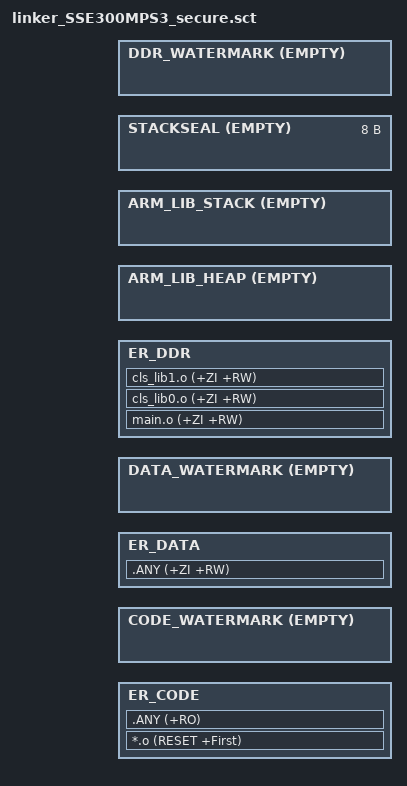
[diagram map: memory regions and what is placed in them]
#! armclang --target=arm-arm-none-eabi -march=armv8.1-m.main -E -xc

;/*
; * Copyright (c) 2018-2023 Arm Limited
; *
; * Licensed under the Apache License, Version 2.0 (the "License");
; * you may not use this file except in compliance with the License.
; * You may obtain a copy of the License at
; *
; *     http://www.apache.org/licenses/LICENSE-2.0
; *
; * Unless required by applicable law or agreed to in writing, software
; * distributed under the License is distributed on an "AS IS" BASIS,
; * WITHOUT WARRANTIES OR CONDITIONS OF ANY KIND, either express or implied.
; * See the License for the specific language governing permissions and
; * limitations under the License.
; *
; */
#include "region_defs.h"

LR_CODE S_CODE_START {
    ER_CODE S_CODE_START {
        *.o (RESET +First)
        .ANY (+RO)
    }
    CODE_WATERMARK +0 EMPTY 0x0 {
    }
    ScatterAssert(ImageLimit(CODE_WATERMARK) <= S_CODE_LIMIT)

    ER_DATA S_DATA_START {
        .ANY (+ZI +RW)
    }
    DATA_WATERMARK +0 EMPTY 0x0 {
    }
    ScatterAssert(ImageLimit(DATA_WATERMARK) <= S_DATA_LIMIT)
	
	ER_DDR S_DDR4_START {
		main.o (+ZI +RW)
		cls_lib0.o (+ZI +RW)
		cls_lib1.o (+ZI +RW)
    }
    ARM_LIB_HEAP +0 ALIGN 8 EMPTY  HEAP_SIZE  {   ; Reserve empty region for heap
    }
    ARM_LIB_STACK +0 ALIGN 32 EMPTY STACK_SIZE - 0x8 {   ; Reserve empty region for stack
    }
    STACKSEAL +0 EMPTY 0x8 {
    }
    DDR_WATERMARK +0 EMPTY 0x0 {
    }
    ScatterAssert(ImageLimit(DDR_WATERMARK) <= S_DDR4_LIMIT)
}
